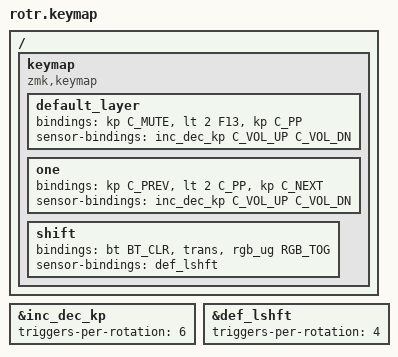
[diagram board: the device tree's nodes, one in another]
#include <behaviors.dtsi>
#include <dt-bindings/zmk/keys.h>
#include <dt-bindings/zmk/rgb.h>
#include <dt-bindings/zmk/bt.h>

&inc_dec_kp {
	triggers-per-rotation = <6>;
};
&def_lshft {
	triggers-per-rotation = <4>;
};

/ {
	keymap {
		compatible = "zmk,keymap";

		default_layer {
			//PREV | PLAY/PAUSE | NEXT
			bindings = <&kp C_MUTE &lt 2 F13 &kp C_PP>;
			sensor-bindings = <&inc_dec_kp C_VOL_UP C_VOL_DN>;
		};
		one {
			//PREV | PLAY/PAUSE | NEXT
			bindings = <&kp C_PREV &lt 2 C_PP &kp C_NEXT>;
			sensor-bindings = <&inc_dec_kp C_VOL_UP C_VOL_DN>;
		};
		shift {
			//PREV | PLAY/PAUSE | NEXT
			bindings = <&bt BT_CLR &trans &rgb_ug RGB_TOG>;
			sensor-bindings = <&def_lshft>;
		};
	};
};
